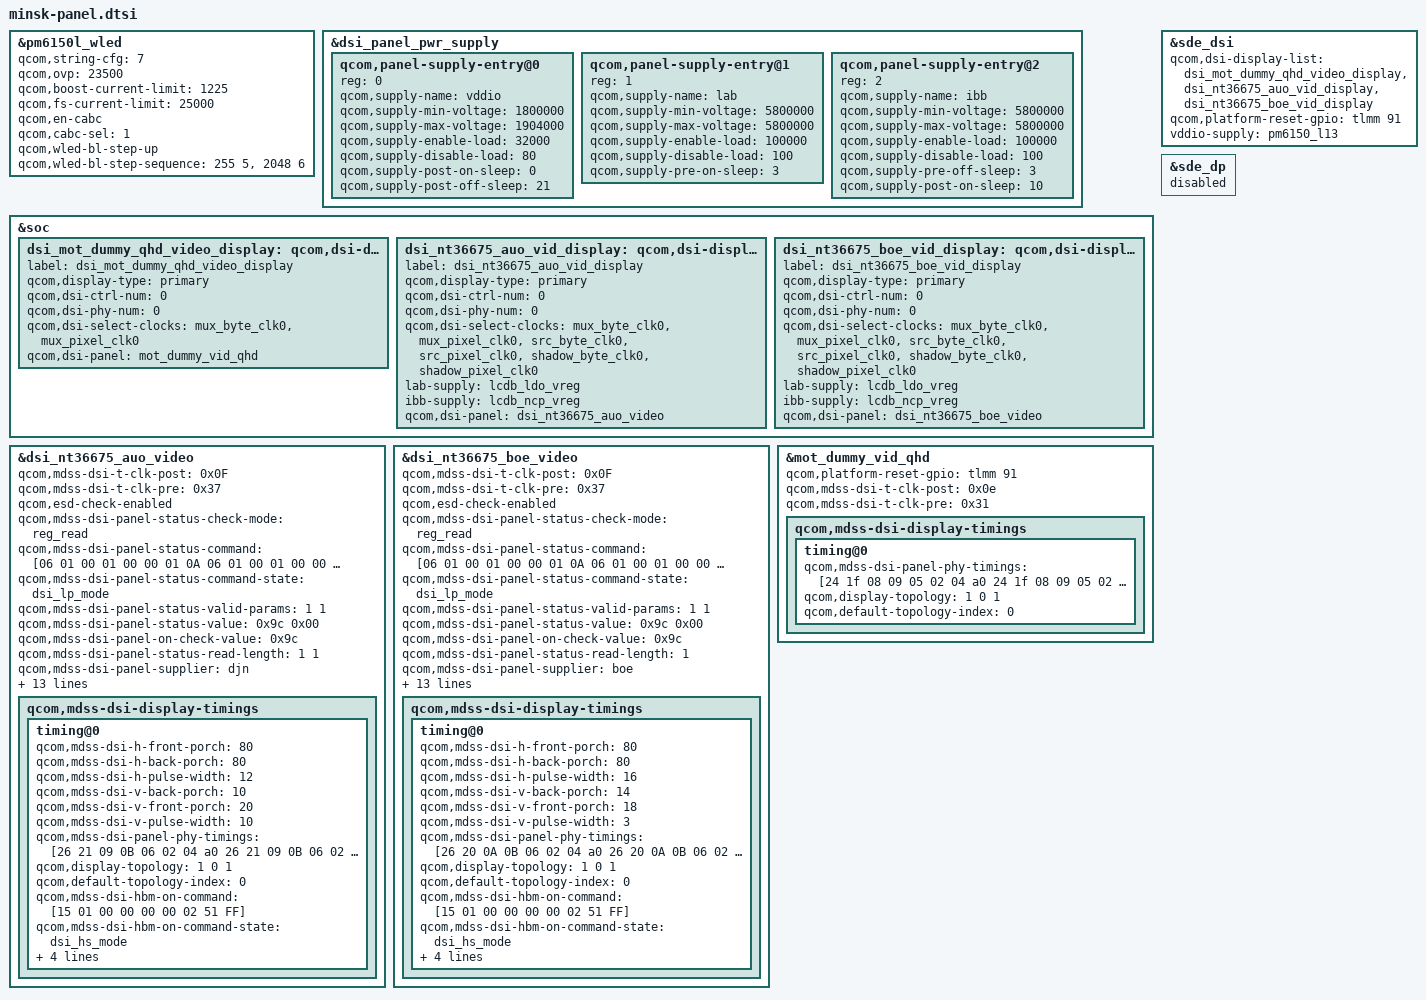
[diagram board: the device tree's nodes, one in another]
/*
 * Copyright (c) 2019, The Linux Foundation. All rights reserved.
 *
 * This program is free software; you can redistribute it and/or modify
 * it under the terms of the GNU General Public License version 2 and
 * only version 2 as published by the Free Software Foundation.
 *
 * This program is distributed in the hope that it will be useful,
 * but WITHOUT ANY WARRANTY; without even the implied warranty of
 * MERCHANTABILITY or FITNESS FOR A PARTICULAR PURPOSE.  See the
 * GNU General Public License for more details.
 */
#include "dsi-panel-mot-auo-nt36675-fhd-video.dtsi"
#include "dsi-panel-mot-boe-nt36675-fhd-video.dtsi"


&pm6150l_wled {
	qcom,string-cfg= <7>;
	qcom,ovp = <23500>;
	qcom,boost-current-limit = <1225>;
	status = "ok";
};

&dsi_panel_pwr_supply {
	qcom,panel-supply-entry@0 {
		reg = <0>;
		qcom,supply-name = "vddio";
		qcom,supply-min-voltage = <1800000>;
		qcom,supply-max-voltage = <1904000>;
		qcom,supply-enable-load = <32000>;
		qcom,supply-disable-load = <80>;
		qcom,supply-post-on-sleep= <0>;
		qcom,supply-post-off-sleep = <21>;
	};

	qcom,panel-supply-entry@1 {
		reg = <1>;
		qcom,supply-name = "lab";
		qcom,supply-min-voltage = <5800000>;
		qcom,supply-max-voltage = <5800000>;
		qcom,supply-enable-load = <100000>;
		qcom,supply-disable-load = <100>;
		qcom,supply-pre-on-sleep = <3>;
	};

	qcom,panel-supply-entry@2 {
		reg = <2>;
		qcom,supply-name = "ibb";
		qcom,supply-min-voltage = <5800000>;
		qcom,supply-max-voltage = <5800000>;
		qcom,supply-enable-load = <100000>;
		qcom,supply-disable-load = <100>;
		qcom,supply-pre-off-sleep = <3>;
		qcom,supply-post-on-sleep = <10>;
	};
};

&soc {
	dsi_mot_dummy_qhd_video_display: qcom,dsi-display@10 {
		label = "dsi_mot_dummy_qhd_video_display";
		qcom,display-type = "primary";

		qcom,dsi-ctrl-num = <0>;
		qcom,dsi-phy-num = <0>;
		qcom,dsi-select-clocks = "mux_byte_clk0", "mux_pixel_clk0";

		qcom,dsi-panel = <&mot_dummy_vid_qhd>;
	};
	dsi_nt36675_auo_vid_display: qcom,dsi-display@11 {
		label = "dsi_nt36675_auo_vid_display";
		qcom,display-type = "primary";

		qcom,dsi-ctrl-num = <0>;
		qcom,dsi-phy-num = <0>;
		qcom,dsi-select-clocks = "mux_byte_clk0", "mux_pixel_clk0",
			"src_byte_clk0", "src_pixel_clk0",
			"shadow_byte_clk0", "shadow_pixel_clk0";
		lab-supply = <&lcdb_ldo_vreg>;
		ibb-supply = <&lcdb_ncp_vreg>;
		qcom,dsi-panel = <&dsi_nt36675_auo_video>;
	};
	dsi_nt36675_boe_vid_display: qcom,dsi-display@12 {
		label = "dsi_nt36675_boe_vid_display";
		qcom,display-type = "primary";

		qcom,dsi-ctrl-num = <0>;
		qcom,dsi-phy-num = <0>;
		qcom,dsi-select-clocks = "mux_byte_clk0", "mux_pixel_clk0",
			"src_byte_clk0", "src_pixel_clk0",
			"shadow_byte_clk0", "shadow_pixel_clk0";
		lab-supply = <&lcdb_ldo_vreg>;
		ibb-supply = <&lcdb_ncp_vreg>;
		qcom,dsi-panel = <&dsi_nt36675_boe_video>;
	};
};

&sde_dsi {
	qcom,dsi-display-list = <
		&dsi_mot_dummy_qhd_video_display
		&dsi_nt36675_auo_vid_display
		&dsi_nt36675_boe_vid_display>;

        /delete-property/ qcom,platform-te-gpio;
	/delete-property/ vddio-supply;
	qcom,platform-reset-gpio = <&tlmm 91 0>;
	vddio-supply = <&pm6150_l13>;
};

&dsi_nt36675_auo_video {
	qcom,mdss-dsi-t-clk-post = <0x0F>;
	qcom,mdss-dsi-t-clk-pre = <0x37>;
	qcom,esd-check-enabled;
	qcom,mdss-dsi-panel-status-check-mode = "reg_read";
	qcom,mdss-dsi-panel-status-command = [06 01 00 01 00 00 01 0A
				06 01 00 01 00 00 01 05];
	qcom,mdss-dsi-panel-status-command-state = "dsi_lp_mode";
	qcom,mdss-dsi-panel-status-valid-params = <1 1>;
	qcom,mdss-dsi-panel-status-value = <0x9c 0x00>;
	qcom,mdss-dsi-panel-on-check-value = <0x9c>;
	qcom,mdss-dsi-panel-status-read-length = <1 1>;
	/*qcom,mdss-dsi-no-panel-on-read-support;*/
	qcom,mdss-dsi-panel-supplier = "djn";
	qcom,tp_state_check_enable;
	qcom,mdss-dsi-reset-sequence = <1 10>, <0 10>, <1 10>;
	qcom,mdss-pan-physical-width-dimension = <71>;
	qcom,mdss-pan-physical-height-dimension = <158>;
	qcom,mdss-dsi-display-timings {
		timing@0{
			qcom,mdss-dsi-h-front-porch = <80>;
			qcom,mdss-dsi-h-back-porch = <80>;
			qcom,mdss-dsi-h-pulse-width = <12>;
			qcom,mdss-dsi-v-back-porch = <10>;
			qcom,mdss-dsi-v-front-porch = <20>;
			qcom,mdss-dsi-v-pulse-width = <10>;
			qcom,mdss-dsi-panel-phy-timings =
				[26 21 09 0B 06 02 04 a0
				26 21 09 0B 06 02 04 a0
				26 21 09 0B 06 02 04 a0
				26 21 09 0B 06 02 04 a0
				26 20 0A 0B 06 02 04 a0];
			qcom,display-topology = <1 0 1>;
			qcom,default-topology-index = <0>;
			qcom,mdss-dsi-hbm-on-command = [15 01 00 00 00 00 02 51 FF];
			qcom,mdss-dsi-hbm-on-command-state =  "dsi_hs_mode";
			qcom,mdss-dsi-hbm-off-command = [15 01 00 00 00 00 02 51 CC];
			qcom,mdss-dsi-hbm-off-command-state =  "dsi_hs_mode";
		};
	};
};

&dsi_nt36675_auo_video {
	qcom,mdss-dsi-bl-pmic-control-type = "bl_ctrl_wled";
	qcom,mdss-dsi-bl-min-level = <47>;
	qcom,mdss-dsi-bl-max-level = <4095>;
	qcom,mdss-dsi-bl-default-level = <2047>;
	qcom,mdss-brightness-max-level = <4095>;
	qcom,platform-reset-gpio = <&tlmm 91 0>;
	qcom,panel-supply-entries = <&dsi_panel_pwr_supply>;
};

&dsi_nt36675_boe_video {
	qcom,mdss-dsi-t-clk-post = <0x0F>;
	qcom,mdss-dsi-t-clk-pre = <0x37>;
	qcom,esd-check-enabled;
	qcom,mdss-dsi-panel-status-check-mode = "reg_read";
	qcom,mdss-dsi-panel-status-command = [06 01 00 01 00 00 01 0A
				06 01 00 01 00 00 01 05];
	qcom,mdss-dsi-panel-status-command-state = "dsi_lp_mode";
	qcom,mdss-dsi-panel-status-valid-params = <1 1>;
	qcom,mdss-dsi-panel-status-value = <0x9c 0x00>;
	qcom,mdss-dsi-panel-on-check-value = <0x9c>;
	qcom,mdss-dsi-panel-status-read-length = <1>;
	/*qcom,mdss-dsi-no-panel-on-read-support;*/
	qcom,mdss-dsi-panel-supplier = "boe";
	qcom,tp_state_check_enable;
	qcom,mdss-dsi-reset-sequence = <1 10>, <0 10>, <1 10>;
	qcom,mdss-pan-physical-width-dimension = <71>;
	qcom,mdss-pan-physical-height-dimension = <158>;
	qcom,mdss-dsi-display-timings {
		timing@0{
			qcom,mdss-dsi-h-front-porch = <80>;
			qcom,mdss-dsi-h-back-porch = <80>;
			qcom,mdss-dsi-h-pulse-width = <16>;
			qcom,mdss-dsi-v-back-porch = <14>;
			qcom,mdss-dsi-v-front-porch = <18>;
			qcom,mdss-dsi-v-pulse-width = <3>;
			qcom,mdss-dsi-panel-phy-timings =
				[26 20 0A 0B 06 02 04 a0
				26 20 0A 0B 06 02 04 a0
				26 20 0A 0B 06 02 04 a0
				26 20 0A 0B 06 02 04 a0
				26 20 0A 0B 06 02 04 a0];
			qcom,display-topology = <1 0 1>;
			qcom,default-topology-index = <0>;
			qcom,mdss-dsi-hbm-on-command = [15 01 00 00 00 00 02 51 FF];
			qcom,mdss-dsi-hbm-on-command-state =  "dsi_hs_mode";
			qcom,mdss-dsi-hbm-off-command = [15 01 00 00 00 00 02 51 CC];
			qcom,mdss-dsi-hbm-off-command-state =  "dsi_hs_mode";
		};
	};
};

&dsi_nt36675_boe_video {
	qcom,mdss-dsi-bl-pmic-control-type = "bl_ctrl_wled";
	qcom,mdss-dsi-bl-min-level = <47>;
	qcom,mdss-dsi-bl-max-level = <4095>;
	qcom,mdss-dsi-bl-default-level = <2047>;
	qcom,mdss-brightness-max-level = <4095>;
	qcom,platform-reset-gpio = <&tlmm 91 0>;
	qcom,panel-supply-entries = <&dsi_panel_pwr_supply>;
};

&mot_dummy_vid_qhd {
	//qcom,platform-te-gpio = <&tlmm 90 0>;
	qcom,platform-reset-gpio = <&tlmm 91 0>;

	qcom,mdss-dsi-t-clk-post = <0x0e>;
	qcom,mdss-dsi-t-clk-pre = <0x31>;
	qcom,mdss-dsi-display-timings {
		timing@0{
			qcom,mdss-dsi-panel-phy-timings =
				[24 1f 08 09 05 02 04 a0
				24 1f 08 09 05 02 04 a0
				24 1f 08 09 05 02 04 a0
				24 1f 08 09 05 02 04 a0
				24 1c 08 09 05 02 04 a0];

			qcom,display-topology = <1 0 1>;
			qcom,default-topology-index = <0>;
		};
	};
};

&pm6150l_wled {
	qcom,fs-current-limit = <25000>;
	qcom,en-cabc;
	qcom,cabc-sel = <1>;


	qcom,wled-bl-step-up;
	qcom,wled-bl-step-sequence = <255 5>, <2048 6>;
};

&sde_dp {
	status = "disable";
};
